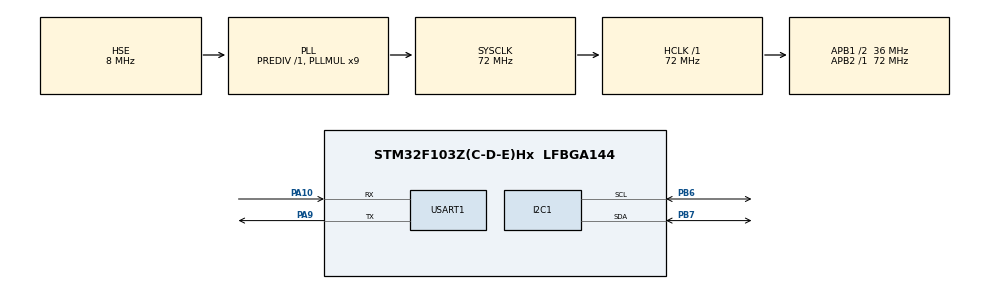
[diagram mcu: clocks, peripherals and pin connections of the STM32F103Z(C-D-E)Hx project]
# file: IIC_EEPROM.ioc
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I2C1.I2C_Mode=I2C_Fast
Mcu.Family=STM32F1
Mcu.Name=STM32F103Z(C-D-E)Hx
Mcu.Package=LFBGA144
NVIC.PriorityGroup=NVIC_PRIORITYGROUP_4
OSC_IN.Mode=HSE-External-Oscillator
OSC_IN.Signal=RCC_OSC_IN
OSC_OUT.Mode=HSE-External-Oscillator
OSC_OUT.Signal=RCC_OSC_OUT
PA10.Mode=Asynchronous
PA10.Signal=USART1_RX
PA13.Mode=JTAG_5_pin
PA13.Signal=SYS_JTMS-SWDIO
PA14.Mode=JTAG_5_pin
PA14.Signal=SYS_JTCK-SWCLK
PA15.Mode=JTAG_5_pin
PA15.Signal=SYS_JTDI
PA9.Mode=Asynchronous
PA9.Signal=USART1_TX
PB3.Mode=JTAG_5_pin
PB3.Signal=SYS_JTDO-TRACESWO
PB4.Mode=JTAG_5_pin
PB4.Signal=SYS_NJTRST
PB6.Mode=I2C
PB6.Signal=I2C1_SCL
PB7.Mode=I2C
PB7.Signal=I2C1_SDA
ProjectManager.TargetToolchain=MDK-ARM V5
RCC.AHBFreq_Value=72000000
RCC.APB1CLKDivider=RCC_HCLK_DIV2
RCC.APB1Freq_Value=36000000
RCC.APB1TimFreq_Value=72000000
RCC.APB2Freq_Value=72000000
RCC.APB2TimFreq_Value=72000000
RCC.HCLKFreq_Value=72000000
RCC.HSIState=RCC_HSI_ON
RCC.PLLMUL=RCC_PLL_MUL9
RCC.PLLSourceVirtual=RCC_PLLSOURCE_HSE
RCC.SYSCLKFreq_VALUE=72000000
RCC.SYSCLKSource=RCC_SYSCLKSOURCE_PLLCLK
RCC.USBFreq_Value=72000000
board=IIC_EEPROM

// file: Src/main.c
/**
  ******************************************************************************
  * File Name          : main.c
  * Description        : Main program body
  ******************************************************************************
  *
  * COPYRIGHT(c) 2016 STMicroelectronics
  *
  * Redistribution and use in source and binary forms, with or without modification,
  * are permitted provided that the following conditions are met:
  *   1. Redistributions of source code must retain the above copyright notice,
  *      this list of conditions and the following disclaimer.
  *   2. Redistributions in binary form must reproduce the above copyright notice,
  *      this list of conditions and the following disclaimer in the documentation
  *      and/or other materials provided with the distribution.
  *   3. Neither the name of STMicroelectronics nor the names of its contributors
  *      may be used to endorse or promote products derived from this software
  *      without specific prior written permission.
  *
  * THIS SOFTWARE IS PROVIDED BY THE COPYRIGHT HOLDERS AND CONTRIBUTORS "AS IS"
  * AND ANY EXPRESS OR IMPLIED WARRANTIES, INCLUDING, BUT NOT LIMITED TO, THE
  * IMPLIED WARRANTIES OF MERCHANTABILITY AND FITNESS FOR A PARTICULAR PURPOSE ARE
  * DISCLAIMED. IN NO EVENT SHALL THE COPYRIGHT HOLDER OR CONTRIBUTORS BE LIABLE
  * FOR ANY DIRECT, INDIRECT, INCIDENTAL, SPECIAL, EXEMPLARY, OR CONSEQUENTIAL
  * DAMAGES (INCLUDING, BUT NOT LIMITED TO, PROCUREMENT OF SUBSTITUTE GOODS OR
  * SERVICES; LOSS OF USE, DATA, OR PROFITS; OR BUSINESS INTERRUPTION) HOWEVER
  * CAUSED AND ON ANY THEORY OF LIABILITY, WHETHER IN CONTRACT, STRICT LIABILITY,
  * OR TORT (INCLUDING NEGLIGENCE OR OTHERWISE) ARISING IN ANY WAY OUT OF THE USE
  * OF THIS SOFTWARE, EVEN IF ADVISED OF THE POSSIBILITY OF SUCH DAMAGE.
  *
  ******************************************************************************
  */
#include "stm32f1xx_hal.h"

/* USER CODE BEGIN Includes */
#include "UART.h"
#include "IIC.h"
/* USER CODE END Includes */

I2C_HandleTypeDef hi2c1;

UART_HandleTypeDef huart1;

/* USER CODE BEGIN PV */
/* Private variables ---------------------------------------------------------*/

/* USER CODE END PV */

void SystemClock_Config(void);
static void MX_GPIO_Init(void);
static void MX_I2C1_Init(void);
static void MX_USART1_UART_Init(void);

/* USER CODE BEGIN PFP */
/* Private function prototypes -----------------------------------------------*/

/* USER CODE END PFP */

int main(void)
{

  /* MCU Configuration----------------------------------------------------------*/

  /* Reset of all peripherals, Initializes the Flash interface and the Systick. */
  HAL_Init();

  /* Configure the system clock */
  SystemClock_Config();

  /* Initialize all configured peripherals */
  MX_GPIO_Init();
  MX_I2C1_Init();
  MX_USART1_UART_Init();

  /* USER CODE BEGIN 2 */
	I2C_Test();
  /* USER CODE END 2 */

  /* Infinite loop */
  while (1)
  {

  }

}

/** System Clock Configuration
*/
void SystemClock_Config(void)
{

  RCC_OscInitTypeDef RCC_OscInitStruct;
  RCC_ClkInitTypeDef RCC_ClkInitStruct;

  RCC_OscInitStruct.OscillatorType = RCC_OSCILLATORTYPE_HSE;
  RCC_OscInitStruct.HSEState = RCC_HSE_ON;
  RCC_OscInitStruct.HSEPredivValue = RCC_HSE_PREDIV_DIV1;
  RCC_OscInitStruct.PLL.PLLState = RCC_PLL_ON;
  RCC_OscInitStruct.PLL.PLLSource = RCC_PLLSOURCE_HSE;
  RCC_OscInitStruct.PLL.PLLMUL = RCC_PLL_MUL9;
  HAL_RCC_OscConfig(&RCC_OscInitStruct);

  RCC_ClkInitStruct.ClockType = RCC_CLOCKTYPE_SYSCLK|RCC_CLOCKTYPE_PCLK1;
  RCC_ClkInitStruct.SYSCLKSource = RCC_SYSCLKSOURCE_PLLCLK;
  RCC_ClkInitStruct.AHBCLKDivider = RCC_SYSCLK_DIV1;
  RCC_ClkInitStruct.APB1CLKDivider = RCC_HCLK_DIV2;
  RCC_ClkInitStruct.APB2CLKDivider = RCC_HCLK_DIV1;
  HAL_RCC_ClockConfig(&RCC_ClkInitStruct, FLASH_LATENCY_2);

  HAL_SYSTICK_Config(HAL_RCC_GetHCLKFreq()/1000);

  HAL_SYSTICK_CLKSourceConfig(SYSTICK_CLKSOURCE_HCLK);

  /* SysTick_IRQn interrupt configuration */
  HAL_NVIC_SetPriority(SysTick_IRQn, 0, 0);
}

/* I2C1 init function */
void MX_I2C1_Init(void)
{

  hi2c1.Instance = I2C1;
  hi2c1.Init.ClockSpeed = 400000;
  hi2c1.Init.DutyCycle = I2C_DUTYCYCLE_2;
  hi2c1.Init.OwnAddress1 = 0;
  hi2c1.Init.AddressingMode = I2C_ADDRESSINGMODE_7BIT;
  hi2c1.Init.DualAddressMode = I2C_DUALADDRESS_DISABLED;
  hi2c1.Init.OwnAddress2 = 0;
  hi2c1.Init.GeneralCallMode = I2C_GENERALCALL_DISABLED;
  hi2c1.Init.NoStretchMode = I2C_NOSTRETCH_DISABLED;
  HAL_I2C_Init(&hi2c1);

}

/* USART1 init function */
void MX_USART1_UART_Init(void)
{

  huart1.Instance = USART1;
  huart1.Init.BaudRate = 115200;
  huart1.Init.WordLength = UART_WORDLENGTH_8B;
  huart1.Init.StopBits = UART_STOPBITS_1;
  huart1.Init.Parity = UART_PARITY_NONE;
  huart1.Init.Mode = UART_MODE_TX_RX;
  huart1.Init.HwFlowCtl = UART_HWCONTROL_NONE;
  huart1.Init.OverSampling = UART_OVERSAMPLING_16;
  HAL_UART_Init(&huart1);

}

/** Configure pins as
        * Analog
        * Input
        * Output
        * EVENT_OUT
        * EXTI
*/
void MX_GPIO_Init(void)
{

  /* GPIO Ports Clock Enable */
  __GPIOB_CLK_ENABLE();
  __GPIOA_CLK_ENABLE();

}

/************************ (C) COPYRIGHT STMicroelectronics *****END OF FILE****/
